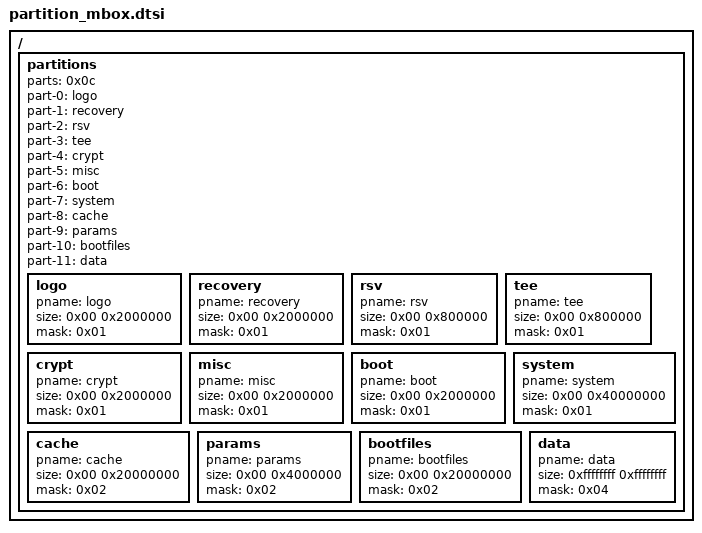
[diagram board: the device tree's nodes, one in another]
/*
 * Amlogic partition set for normal
 *
 * Copyright (c) 2017-2017 Amlogic Ltd
 *
 * This file is licensed under a dual GPLv2 or BSD license.
 *
 */
 / {
	partitions {
		parts = <0x0c>;
		part-0 = <&logo>;
		part-1 = <&recovery>;
		part-2 = <&rsv>;
		part-3 = <&tee>;
		part-4 = <&crypt>;
		part-5 = <&misc>;
		part-6 = <&boot>;
		part-7 = <&system>;
		part-8 = <&cache>;
		part-9 = <&params>;
		part-10 = <&bootfiles>;
		part-11 = <&data>;

		logo:logo {
			pname = "logo";
			size = <0x00 0x2000000>;
			mask = <0x01>;
		};

		recovery:recovery {
			pname = "recovery";
			size = <0x00 0x2000000>;
			mask = <0x01>;
		};

		rsv:rsv {
			pname = "rsv";
			size = <0x00 0x800000>;
			mask = <0x01>;
		};

		tee:tee {
			pname = "tee";
			size = <0x00 0x800000>;
			mask = <0x01>;
		};

		crypt:crypt {
			pname = "crypt";
			size = <0x00 0x2000000>;
			mask = <0x01>;
		};

		misc:misc {
			pname = "misc";
			size = <0x00 0x2000000>;
			mask = <0x01>;
		};

		boot:boot {
			pname = "boot";
			size = <0x00 0x2000000>;
			mask = <0x01>;
		};

		system:system {
			pname = "system";
			size = <0x00 0x40000000>;
			mask = <0x01>;
		};

		cache:cache {
			pname = "cache";
			size = <0x00 0x20000000>;
			mask = <0x02>;
		};

		params:params {
			pname = "params";
			size = <0x00 0x4000000>;
			mask = <0x02>;
		};

		bootfiles:bootfiles {
			pname = "bootfiles";
			size = <0x00 0x20000000>;
			mask = <0x02>;
		};

		data:data {
			pname = "data";
			size = <0xffffffff 0xffffffff>;
			mask = <0x04>;
		};
	};
 };/* end of / */
